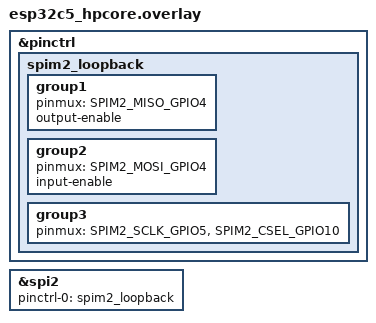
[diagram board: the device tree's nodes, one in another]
/*
 * Copyright (c) 2026 Espressif Systems (Shanghai) Co., Ltd.
 *
 * SPDX-License-Identifier: Apache-2.0
 */

&pinctrl {
	spim2_loopback: spim2_loopback {
		group1 {
			pinmux = <SPIM2_MISO_GPIO4>;
			output-enable; /* Enable internal loopback */
		};

		group2 {
			pinmux = <SPIM2_MOSI_GPIO4>;
			input-enable; /* Enable internal loopback */
		};

		group3 {
			pinmux = <SPIM2_SCLK_GPIO5>,
				 <SPIM2_CSEL_GPIO10>;
		};
	};
};

spi_loopback: &spi2 {
	#address-cells = <1>;
	#size-cells = <0>;
	pinctrl-0 = <&spim2_loopback>;
	pinctrl-names = "default";
	status = "okay";
};

#include "../spi-loopback.dtsi"
